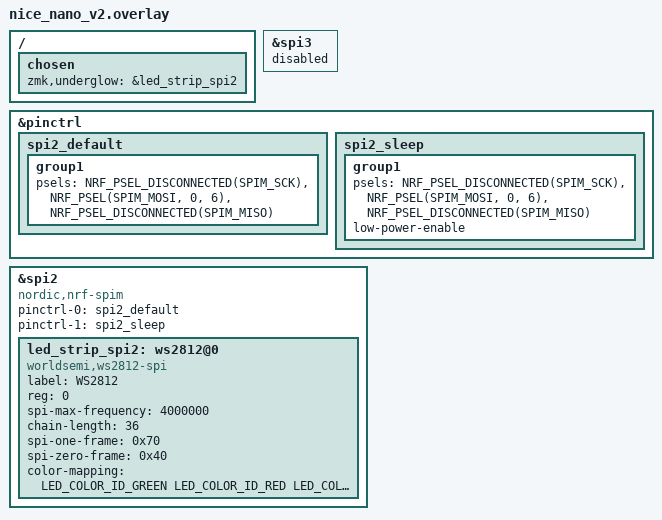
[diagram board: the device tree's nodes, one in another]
#include <dt-bindings/led/led.h>

&spi3 {
    status = "disabled";
};

&pinctrl {
	spi2_default: spi2_default {
		group1 {
			psels =	<NRF_PSEL_DISCONNECTED(SPIM_SCK)>,
				<NRF_PSEL(SPIM_MOSI, 0, 6)>,
				<NRF_PSEL_DISCONNECTED(SPIM_MISO)>;
		};
	};

	spi2_sleep: spi2_sleep {
		group1 {
			psels =	<NRF_PSEL_DISCONNECTED(SPIM_SCK)>,
				<NRF_PSEL(SPIM_MOSI, 0, 6)>,
				<NRF_PSEL_DISCONNECTED(SPIM_MISO)>;
			low-power-enable;
		};
	};
};

&spi2 {
	compatible = "nordic,nrf-spim";
	status = "okay";

	pinctrl-0 = <&spi2_default>;
	pinctrl-1 = <&spi2_sleep>;
	pinctrl-names = "default", "sleep";

	led_strip_spi2: ws2812@0 {
		compatible = "worldsemi,ws2812-spi";
		label = "WS2812";

		/* SPI */
		reg = <0>; /* ignored, but necessary for SPI bindings */
		spi-max-frequency = <4000000>;

		/* WS2812 */
		chain-length = <36>; /* There are per-key RGB, but the first 6 are underglow */
		spi-one-frame = <0x70>;
		spi-zero-frame = <0x40>;
		color-mapping = <LED_COLOR_ID_GREEN LED_COLOR_ID_RED LED_COLOR_ID_BLUE>;
	};
};

/ {
    chosen {
        zmk,underglow = &led_strip_spi2;
    };
};
